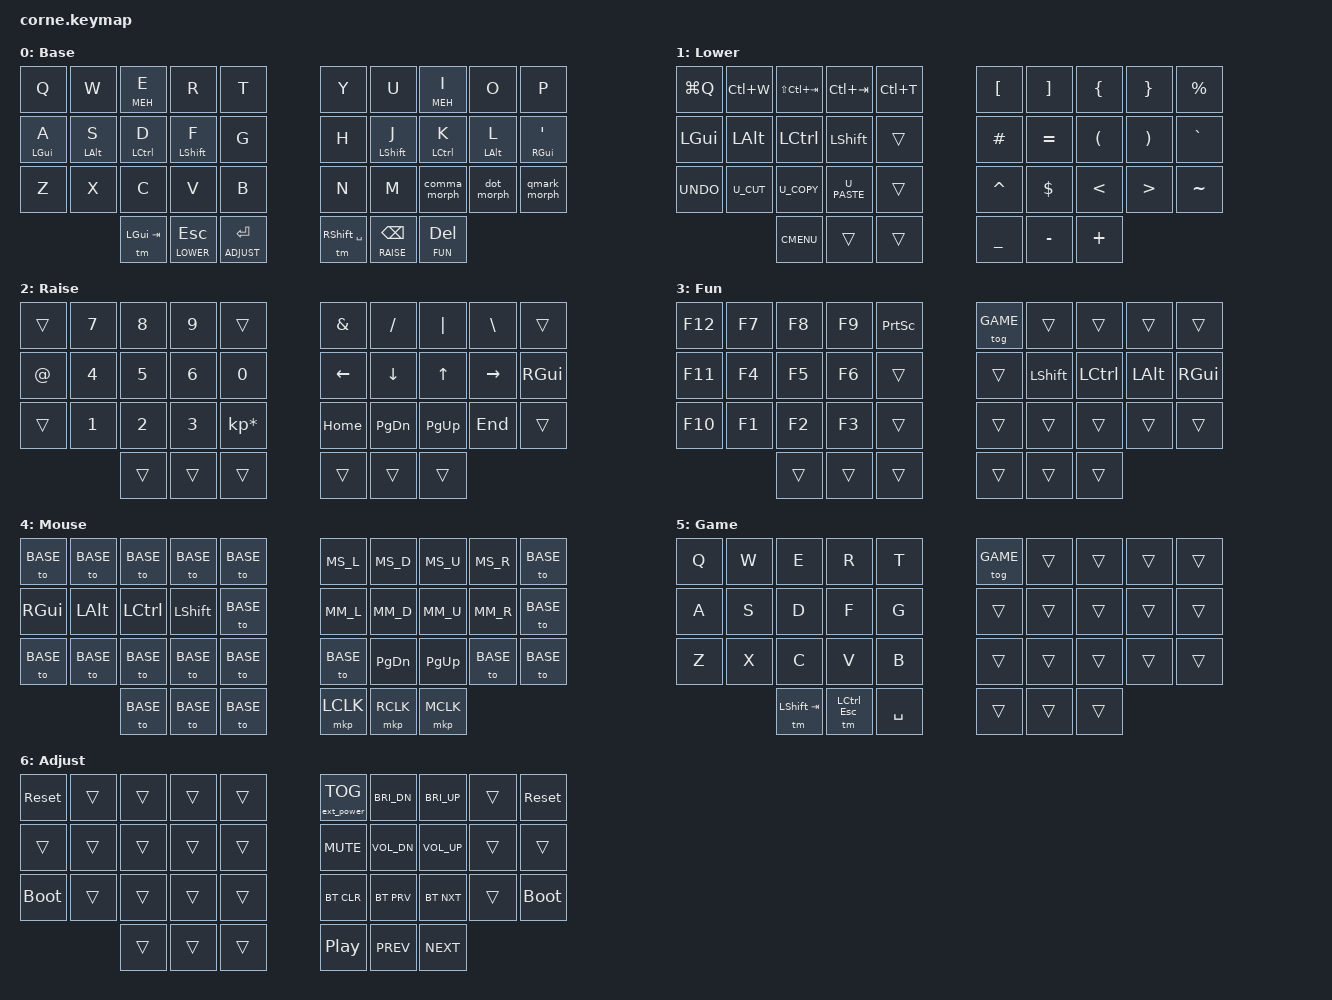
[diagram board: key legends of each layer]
#include <behaviors.dtsi>
#include <dt-bindings/zmk/keys.h>
#include <dt-bindings/zmk/bt.h>
#include <dt-bindings/zmk/ext_power.h>

// Layers
#define BASE  0
#define LOWER 1
#define RAISE 2
#define FUN   3
#define MOUSE 4
#define GAME  5
#define ADJUST 6

// Keys
#define MEH LC(LS(LALT))
#define U_CUT LS(DEL)
#define U_COPY LC(INS)
#define U_PASTE LS(INS)
#define ___ &trans
#define _0_ &to BASE

#include "includes/keys.h"
#include "includes/macros.dtsi"
#include "includes/mouse.dtsi"
#include "includes/mods.dtsi"
#include "includes/dance.dtsi"
#include "includes/combos.dtsi"
#include "includes/morphs.dtsi"
#include "includes/settings.dtsi"

/ {

  chosen {
      zmk,matrix_transform = &five_column_transform;
  };

  keymap {
    compatible = "zmk,keymap";

    base_layer {
      display-name = "Base";
      bindings = <
//    ╭─────────────┬─────────────┬──────────────┬──────────────┬──────────────╮                                ╭───────────────┬─────────────┬──────────────┬─────────────┬──────────────╮
//    │      Q      │      W      │  &hml MEH E  │      R       │      T       │                                │       Y       │      U      │  &hmr MEH I  │      O      │      P       │
//    ├─────────────┼─────────────┼──────────────┼──────────────┼──────────────┤                                ├───────────────┼─────────────┼──────────────┼─────────────┼──────────────┤
//    │ &hml LGUI A │ &hml LALT S │ &hml LCTRL D │ &hml LSFT F  │      G       │                                │       H       │ &hmr LSFT J │ &hmr LCTRL K │ &hmr LALT L │ &hmr RGUI '  │
//    ├─────────────┼─────────────┼──────────────┼──────────────┼──────────────┤                                ├───────────────┼─────────────┼──────────────┼─────────────┼──────────────┤
//    │      Z      │      X      │      C       │      V       │      B       │                                │       N       │      M      │ &comma_morph │ &dot_morph  │ &qmark_morph │
//    ╰─────────────┴─────────────┴──────────────┼──────────────┼──────────────┼───────────────┬────────────────┼───────────────┼─────────────┼──────────────┴─────────────┴──────────────╯
//                                               │ &tm LGUI TAB │ LT LOWER ESC │ LT ADJUST ENT │ &tm RSFT SPACE │ LT RAISE BSPC │ LT FUN DEL  │
//                                               ╰──────────────┴──────────────┴───────────────┴────────────────┴───────────────┴─────────────╯
  &kp Q         &kp W         &hml MEH E     &kp R          &kp T                                              &kp Y            &kp U          &hmr MEH I     &kp O         &kp P
  &hml LGUI A   &hml LALT S   &hml LCTRL D   &hml LSHFT F   &kp G                                              &kp H            &hmr LSHFT J   &hmr LCTRL K   &hmr LALT L   &hmr RGUI SQT
  &kp Z         &kp X         &kp C          &kp V          &kp B                                              &kp N            &kp M          &comma_morph   &dot_morph    &qmark_morph
                                             &tm LGUI TAB   &lt LOWER ESC   &lt ADJUST RET   &tm RSHFT SPACE   &lt RAISE BSPC   &lt FUN DEL
      >;
    };

    lower_layer {
      display-name = "Lower";
      bindings = <
//    ╭──────┬──────┬───────┬──────┬────╮       ╭───┬───┬───┬───┬───╮
//    │  ⌘Q  │  ⌃W  │  ⇧⌃⇥  │  ⌃⇥  │ ⌃T │       │ [ │ ] │ { │ } │ % │
//    ├──────┼──────┼───────┼──────┼────┤       ├───┼───┼───┼───┼───┤
//    │ LGUI │ LALT │ LCTRL │ LSFT │    │       │ # │ = │ ( │ ) │ ` │
//    ├──────┼──────┼───────┼──────┼────┤       ├───┼───┼───┼───┼───┤
//    │  ↩️  │  ✂️  │  📄   │  📋  │    │       │ ^ │ $ │ < │ > │ ~ │
//    ╰──────┴──────┴───────┼──────┼────┼───┬───┼───┼───┼───┴───┴───╯
//                          │  🌍  │    │   │ _ │ - │ + │
//                          ╰──────┴────┴───┴───┴───┴───╯
  &kp LG(Q)    &kp LC(W)   &kp LS(LC(TAB))   &kp LC(TAB)   &kp LC(T)                          &kp LBKT    &kp RBKT     &kp LBRC   &kp RBRC   &kp PRCNT
  &kp LGUI     &kp LALT    &kp LCTRL         &kp LSHFT     ___                                &kp HASH    &kp EQUAL    &kp LPAR   &kp RPAR   &kp GRAVE
  &kp K_UNDO   &kp U_CUT   &kp U_COPY        &kp U_PASTE   ___                                &kp CARET   &kp DOLLAR   &kp LT     &kp GT     &kp TILDE
                                             &kp K_CMENU   ___         ___   &kp UNDERSCORE   &kp MINUS   &kp PLUS
      >;
    };

    raise_layer {
      display-name = "Raise";
      bindings = <
//    ╭───┬───┬───┬───┬───╮       ╭───┬───┬───┬───┬──────╮
//    │   │ 7 │ 8 │ 9 │   │       │ & │ / │ | │ \ │      │
//    ├───┼───┼───┼───┼───┤       ├───┼───┼───┼───┼──────┤
//    │ @ │ 4 │ 5 │ 6 │ 0 │       │ ← │ ↓ │ ↑ │ → │ RGUI │
//    ├───┼───┼───┼───┼───┤       ├───┼───┼───┼───┼──────┤
//    │   │ 1 │ 2 │ 3 │ * │       │ ⇱ │ ⇟ │ ⇞ │ ⇲ │      │
//    ╰───┴───┴───┼───┼───┼───┬───┼───┼───┼───┴───┴──────╯
//                │   │   │   │   │   │   │
//                ╰───┴───┴───┴───┴───┴───╯
  ___      &kp N7   &kp N8   &kp N9   ___                           &kp AMPS   &kp FSLH    &kp PIPE    &kp BSLH    ___
  &kp AT   &kp N4   &kp N5   &kp N6   &kp N0                        &kp LEFT   &kp DOWN    &kp UP      &kp RIGHT   &kp RGUI
  ___      &kp N1   &kp N2   &kp N3   &kp KP_MULTIPLY               &kp HOME   &kp PG_DN   &kp PG_UP   &kp END     ___
                             ___      ___               ___   ___   ___        ___
      >;
    };

    fun_layer {
      display-name = "Fun";
      bindings = <
//    ╭─────┬────┬────┬────┬──────╮       ╭───┬──────┬───────┬──────┬──────╮
//    │ F12 │ F7 │ F8 │ F9 │ PSCR │       │   │      │       │      │      │
//    ├─────┼────┼────┼────┼──────┤       ├───┼──────┼───────┼──────┼──────┤
//    │ F11 │ F4 │ F5 │ F6 │      │       │   │ LSFT │ LCTRL │ LALT │ RGUI │
//    ├─────┼────┼────┼────┼──────┤       ├───┼──────┼───────┼──────┼──────┤
//    │ F10 │ F1 │ F2 │ F3 │      │       │   │      │       │      │      │
//    ╰─────┴────┴────┼────┼──────┼───┬───┼───┼──────┼───────┴──────┴──────╯
//                    │    │      │   │   │   │      │
//                    ╰────┴──────┴───┴───┴───┴──────╯
  &kp F12   &kp F7   &kp F8   &kp F9   &kp PSCRN               &tog GAME   ___         ___         ___        ___
  &kp F11   &kp F4   &kp F5   &kp F6   ___                     ___         &kp LSHFT   &kp LCTRL   &kp LALT   &kp RGUI
  &kp F10   &kp F1   &kp F2   &kp F3   ___                     ___         ___         ___         ___        ___
                              ___      ___         ___   ___   ___         ___
      >;
    };

    mouse_layer {
      display-name = "Mouse";
      bindings = <
//    ╭──────┬──────┬───────┬──────┬───╮         ╭─────┬─────┬─────┬─────┬───╮
//    │      │      │       │      │   │         │ 🖱️⇇ │ 🖱️⇊ │ 🖱️⇈ │ 🖱️⇉ │   │
//    ├──────┼──────┼───────┼──────┼───┤         ├─────┼─────┼─────┼─────┼───┤
//    │ RGUI │ LALT │ LCTRL │ LSFT │   │         │ 🖱️← │ 🖱️↓ │ 🖱️↑ │ 🖱️→ │   │
//    ├──────┼──────┼───────┼──────┼───┤         ├─────┼─────┼─────┼─────┼───┤
//    │      │      │       │      │   │         │     │  ⇟  │  ⇞  │     │   │
//    ╰──────┴──────┴───────┼──────┼───┼───┬─────┼─────┼─────┼─────┴─────┴───╯
//                          │      │   │   │ 🖱️L │ 🖱️R │ 🖱️M │
//                          ╰──────┴───┴───┴─────┴─────┴─────╯
  _0_        _0_        _0_         _0_         _0_                     _MS_L       _MS_D       _MS_U       _MS_R   _0_
  &kp RGUI   &kp LALT   &kp LCTRL   &kp LSHFT   _0_                     _MM_L       _MM_D       _MM_U       _MM_R   _0_
  _0_        _0_        _0_         _0_         _0_                     _0_         &kp PG_DN   &kp PG_UP   _0_     _0_
                                    _0_         _0_   _0_   &mkp LCLK   &mkp RCLK   &mkp MCLK
      >;
    };

    gaming_layer {
      display-name = "Game";
      bindings = <
//    Left side: standard QWERTY. Left two thumb keys are tap-hold Tab/Esc with Shift/Ctrl on hold; Space on left inner thumb.
//    Right side: passthrough (with an exit toggle).
  &kp Q     &kp W     &kp E     &kp R     &kp T                           &tog GAME   ___   ___   ___   ___
  &kp A     &kp S     &kp D     &kp F     &kp G                           ___   ___   ___   ___   ___
  &kp Z     &kp X     &kp C     &kp V     &kp B                           ___   ___   ___   ___   ___
                      &tm LSHFT TAB &tm LCTRL ESC &kp SPACE               ___   ___   ___
      >;
    };

    adjust_layer {
      display-name = "Adjust";
      bindings = <
//    ╭────┬───┬───┬───┬───╮        ╭──────┬──────┬──────┬───┬────╮
//    │ 🔄 │   │   │   │   │        │  🔌  │  🔅  │  🔆  │   │ 🔄 │
//    ├────┼───┼───┼───┼───┤        ├──────┼──────┼──────┼───┼────┤
//    │    │   │   │   │   │        │  🔇  │  🔉  │  🔊  │   │    │
//    ├────┼───┼───┼───┼───┤        ├──────┼──────┼──────┼───┼────┤
//    │ 💾 │   │   │   │   │        │ 🛜❌ │ 🛜🔽 │ 🛜🔼 │   │ 💾 │
//    ╰────┴───┴───┼───┼───┼───┬────┼──────┼──────┼──────┴───┴────╯
//                 │   │   │   │ ⏯️ │  ⏮️  │  ⏭️  │
//                 ╰───┴───┴───┴────┴──────┴──────╯
  &sys_reset    ___   ___   ___   ___                    &ext_power EP_TOG   &kp C_BRI_DN   &kp C_BRI_UP   ___   &sys_reset
  ___           ___   ___   ___   ___                    &kp C_MUTE          &kp C_VOL_DN   &kp C_VOL_UP   ___   ___
  &bootloader   ___   ___   ___   ___                    &bt BT_CLR          &bt BT_PRV     &bt BT_NXT     ___   &bootloader
                            ___   ___   ___   &kp C_PP   &kp C_PREV          &kp C_NEXT
      >;
    };

  // empty_layer {
  //   display-name = "Empty";
  //   bindings = <
  //  ___   ___   ___   ___   ___                     ___   ___   ___   ___   ___
  //  ___   ___   ___   ___   ___                     ___   ___   ___   ___   ___
  //  ___   ___   ___   ___   ___                     ___   ___   ___   ___   ___
  //                          ___   ___   ___   ___   ___   ___
  //   >;
  // };
  };
};
